AUTOSAR XML (schema 4-0-3)
standard types defined: Boolean, UInt32
package /AUTOSAR_Platform/DataConstrs
  range DC_Boolean: raw 0..1
package /PATAC/MSM/ComponentTypes
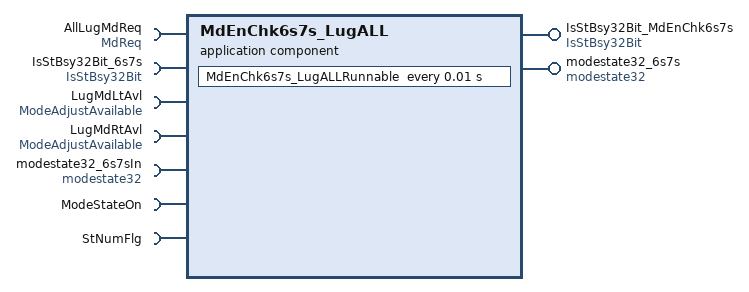
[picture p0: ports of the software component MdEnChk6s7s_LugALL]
  application sw component type MdEnChk6s7s_LugALL
    provide port IsStBsy32Bit_MdEnChk6s7s: nonqueued-sender-com-spec{data-element=IsStBsy32Bit/Val, init-value=0}, provided-interface=IsStBsy32Bit
    provide port modestate32_6s7s: nonqueued-sender-com-spec{data-element=modestate32/Val, init-value=0}, provided-interface=modestate32
    7 x require port:
      AllLugMdReq: nonqueued-receiver-com-spec{data-element=MdReq/Val, filter=data-filter-type=ALWAYS, init-value=0}, required-interface=MdReq
      IsStBsy32Bit_6s7s: nonqueued-receiver-com-spec{data-element=IsStBsy32Bit/Val, filter=data-filter-type=ALWAYS, init-value=0}, required-interface=IsStBsy32Bit
      LugMdLtAvl: nonqueued-receiver-com-spec{data-element=ModeAdjustAvailable/Val, filter=data-filter-type=ALWAYS, init-value=0}, required-interface=ModeAdjustAvailable
      LugMdRtAvl: nonqueued-receiver-com-spec{data-element=ModeAdjustAvailable/Val, filter=data-filter-type=ALWAYS, init-value=0}, required-interface=ModeAdjustAvailable
      modestate32_6s7sIn: nonqueued-receiver-com-spec{data-element=modestate32/Val, filter=data-filter-type=ALWAYS, init-value=0}, required-interface=modestate32
      ModeStateOn: nonqueued-receiver-com-spec{data-element=ModeStateOn/Val, filter=data-filter-type=ALWAYS, init-value=0}, required-interface=ModeStateOn
      StNumFlg: required-interface=StNumFlg
        required-com-specs:
          data-element=Is4s, filter=data-filter-type=ALWAYS, init-value=0
          data-element=Is6s, filter=data-filter-type=ALWAYS, init-value=0
          data-element=Is6s7s, filter=data-filter-type=ALWAYS, init-value=0
          data-element=Is7s, filter=data-filter-type=ALWAYS, init-value=0
    behavior MdEnChk6s7s_LugALL_InternalBehavior
      timing event TMT_MdEnChk4sRunnable: start-on-event=MdEnChk6s7s_LugALLRunnable, period=0.01
      runnable MdEnChk6s7s_LugALLRunnable
        data-receive-point-by-arguments:
          9 x access:
            REC_AllLugMdReq_Val: accessed-variable=AllLugMdReq.Val
            REC_IsStBsy32Bit_6s7s_Val: accessed-variable=IsStBsy32Bit_6s7s.Val
            REC_LugMdLtAvl_Val: accessed-variable=LugMdLtAvl.Val
            REC_LugMdRtAvl_Val: accessed-variable=LugMdRtAvl.Val
            REC_modestate32_MdEnClearOut_Val: accessed-variable=modestate32_6s7sIn.Val
            REC_ModeStateOn_Val: accessed-variable=ModeStateOn.Val
            REC_StNumFlg_Is6s: accessed-variable=StNumFlg.Is6s
            REC_StNumFlg_Is6s7s: accessed-variable=StNumFlg.Is6s7s
            REC_StNumFlg_Is7s: accessed-variable=StNumFlg.Is7s
        data-send-points:
          access SEND_IsStBsy32Bit_MdEnChk6s7s_Val: accessed-variable=IsStBsy32Bit_MdEnChk6s7s.Val
          access SEND_modestate32_6s7s_Val: accessed-variable=modestate32_6s7s.Val
  swc implementation MdEnChk6s7s_LugALL_Implementation: behavior=MdEnChk6s7s_LugALL_InternalBehavior
    code-descriptors:
      code Default: artifact-descriptors=autosar-engineering-object={short-label=Default, category=SWSRC}
package /PATAC/MSM/ModeAdjust/PortInterface
  6 x sender receiver interface:
    IsStBsy32Bit: invalidation-policy{data-element=IsStBsy32Bit/Val, handle-invalid=DONT-INVALIDATE}
      data Val: type=UInt32
    MdReq: invalidation-policy{data-element=MdReq/Val, handle-invalid=DONT-INVALIDATE}
      data Val: type=Boolean
    ModeAdjustAvailable: invalidation-policy{data-element=ModeAdjustAvailable/Val, handle-invalid=DONT-INVALIDATE}
      data Val: type=Boolean
    modestate32: invalidation-policy{data-element=modestate32/Val, handle-invalid=DONT-INVALIDATE}
      data Val: type=UInt32
    ModeStateOn: invalidation-policy{data-element=ModeStateOn/Val, handle-invalid=DONT-INVALIDATE}
      data Val: type=Boolean
    StNumFlg
      4 x data, all with type=Boolean:
        Is4s
        Is6s
        Is6s7s
        Is7s
      invalidation-policys:
        data-element=Is7s, handle-invalid=DONT-INVALIDATE
        data-element=Is6s, handle-invalid=DONT-INVALIDATE
        data-element=Is4s, handle-invalid=DONT-INVALIDATE
        data-element=Is6s7s, handle-invalid=DONT-INVALIDATE
